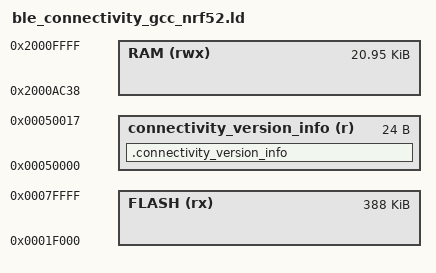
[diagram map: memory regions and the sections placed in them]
/* Linker script to configure memory regions. */

SEARCH_DIR(.)
GROUP(-lgcc -lc -lnosys)

MEMORY
{
  FLASH (rx) : ORIGIN = 0x1f000, LENGTH = 0x61000
  RAM (rwx) :  ORIGIN = 0x2000ac38, LENGTH = 0x53c8
  connectivity_version_info (r) : ORIGIN = 0x50000, LENGTH = 0x18
}

SECTIONS
{
  . = ALIGN(4);
  .connectivity_version_info :
  {
    PROVIDE(__start_connectivity_version_info = .);
    KEEP(*(SORT(.connectivity_version_info*)))
    PROVIDE(__stop_connectivity_version_info = .);
  } > connectivity_version_info
}

SECTIONS
{
  . = ALIGN(4);
  .mem_section_dummy_ram :
  {
  }
  .log_dynamic_data :
  {
    PROVIDE(__start_log_dynamic_data = .);
    KEEP(*(SORT(.log_dynamic_data*)))
    PROVIDE(__stop_log_dynamic_data = .);
  } > RAM
  .log_filter_data :
  {
    PROVIDE(__start_log_filter_data = .);
    KEEP(*(SORT(.log_filter_data*)))
    PROVIDE(__stop_log_filter_data = .);
  } > RAM

} INSERT AFTER .data;

SECTIONS
{
  .mem_section_dummy_rom :
  {
  }
  .sdh_ble_observers :
  {
    PROVIDE(__start_sdh_ble_observers = .);
    KEEP(*(SORT(.sdh_ble_observers*)))
    PROVIDE(__stop_sdh_ble_observers = .);
  } > FLASH
  .sdh_soc_observers :
  {
    PROVIDE(__start_sdh_soc_observers = .);
    KEEP(*(SORT(.sdh_soc_observers*)))
    PROVIDE(__stop_sdh_soc_observers = .);
  } > FLASH
    .nrf_queue :
  {
    PROVIDE(__start_nrf_queue = .);
    KEEP(*(.nrf_queue))
    PROVIDE(__stop_nrf_queue = .);
  } > FLASH
  .log_const_data :
  {
    PROVIDE(__start_log_const_data = .);
    KEEP(*(SORT(.log_const_data*)))
    PROVIDE(__stop_log_const_data = .);
  } > FLASH
    .nrf_balloc :
  {
    PROVIDE(__start_nrf_balloc = .);
    KEEP(*(.nrf_balloc))
    PROVIDE(__stop_nrf_balloc = .);
  } > FLASH
  .sdh_state_observers :
  {
    PROVIDE(__start_sdh_state_observers = .);
    KEEP(*(SORT(.sdh_state_observers*)))
    PROVIDE(__stop_sdh_state_observers = .);
  } > FLASH
  .sdh_stack_observers :
  {
    PROVIDE(__start_sdh_stack_observers = .);
    KEEP(*(SORT(.sdh_stack_observers*)))
    PROVIDE(__stop_sdh_stack_observers = .);
  } > FLASH
  .sdh_req_observers :
  {
    PROVIDE(__start_sdh_req_observers = .);
    KEEP(*(SORT(.sdh_req_observers*)))
    PROVIDE(__stop_sdh_req_observers = .);
  } > FLASH
  .log_backends :
  {
    PROVIDE(__start_log_backends = .);
    KEEP(*(SORT(.log_backends*)))
    PROVIDE(__stop_log_backends = .);
  } > FLASH

} INSERT AFTER .text


INCLUDE "nrf_common.ld"
